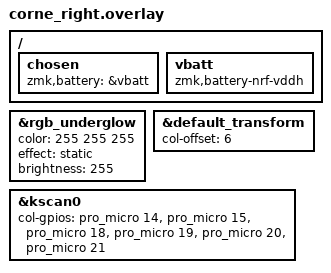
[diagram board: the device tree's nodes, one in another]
/*
 * Copyright (c) 2020 Pete Johanson
 *
 * SPDX-License-Identifier: MIT
 */

#include "corne.dtsi"

//added
&rgb_underglow {
    status = "okay";
    color = <255 255 255>;     // White color for testing (R G B)
    effect = "static";         // Static effect to keep the color on
    brightness = <255>;        // Max brightness
};
//added


&default_transform {
	col-offset = <6>;
};

&kscan0 {
    col-gpios
        = <&pro_micro 14  GPIO_ACTIVE_HIGH>
        , <&pro_micro 15  GPIO_ACTIVE_HIGH>
        , <&pro_micro 18  GPIO_ACTIVE_HIGH>
        , <&pro_micro 19  GPIO_ACTIVE_HIGH>
        , <&pro_micro 20  GPIO_ACTIVE_HIGH>
        , <&pro_micro 21  GPIO_ACTIVE_HIGH>
        ;
};
/ {
    chosen {
      zmk,battery = &vbatt;
    };

    vbatt: vbatt {
        compatible = "zmk,battery-nrf-vddh";
    };
};
